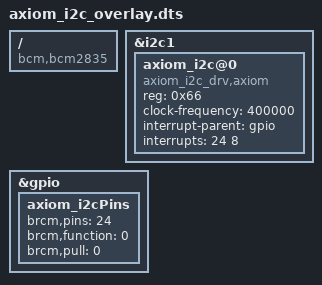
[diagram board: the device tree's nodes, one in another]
/*
 * TouchNetix aXiom Touchscreen Driver
 *
 * Copyright (C) 2020-2023 TouchNetix Ltd.
 *
 * Author(s): Mark Satterthwaite <mark.satterthwaite@touchnetix.com>
 *            Pedro Torruella <pedro.torruella@touchnetix.com>
 *            Bart Prescott <bartp@baasheep.co.uk>
 *            Hannah Rossiter <hannah.rossiter@touchnetix.com> 
 *
 * This program is free software; you can redistribute  it and/or modify it
 * under  the terms of  the GNU General  Public License as published by the
 * Free Software Foundation;  either version 2 of the  License, or (at your
 * option) any later version.
 *
 */

/dts-v1/;
/plugin/;

/ {
	compatible = "bcm,bcm2835", "bcm,bcm2708", "bcm,bcm2709";

	fragment@0 {
		target = <&i2c1>;
		__overlay__ {
			#address-cells = <1>;
			#size-cells = <0>;
			status = "okay";

			axiom_i2c@0 {
					compatible = "axiom_i2c_drv,axiom";
					reg = <0x66>;  /* This must match the I2C ADDR selected on the EVK header, 
									  use either <0x66> or <0x67>, the default is <0x66> */
					clock-frequency = <400000>;
					interrupt-parent = <&gpio>;
					interrupts = < 24 8 >; /* <GPIO Flags> Flags: 1 = lo-to-hi, 2 = hi-to-lo, 4 = active high, 8 = active low  */
					pinctrl-names = "default";
					/* pinctrl-0 = <&axiom_i2cPins>; */
			};		
		};
	};

	fragment@1 {
		target = <&gpio>;
		__overlay__ {
			axiom_i2cPins: axiom_i2cPins {
				brcm,pins = <24>; /* GEN5 on GPIO24 (on Pi Header Pin 18) */
				brcm,function = <0>; /* in */
				brcm,pull = <0>; /* 0 - none, 1 - down, 2 - up : https://github.com/torvalds/linux/blob/master/Documentation/devicetree/bindings/pinctrl/brcm%2Cbcm2835-gpio.txt */
			};
		};
	};
};


